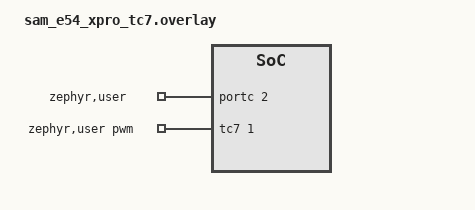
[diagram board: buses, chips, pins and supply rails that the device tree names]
/*
 * Copyright (c) 2025-2026 Microchip Technology Inc.
 * SPDX-License-Identifier: Apache-2.0
 */

/* connect PB01 to PC02 */

#define PWM_NODE     tc7
#define PWM_PINCTRL  tc7_pwm_default
#include "mchp_pwm_loopback_support.dtsi"

/ {
	zephyr,user {
		pwms = <&tc7 1 PWM_MSEC(1) 1>;
		gpios = <&portc 2 GPIO_ACTIVE_HIGH>;
	};
};

&portc {
	status = "okay";
};

&pinctrl {
	tc7_pwm_default: tc7_pwm_default {
		group1 {
			pinmux = <PB1E_TC7_WO1>;
		};
	};
};
